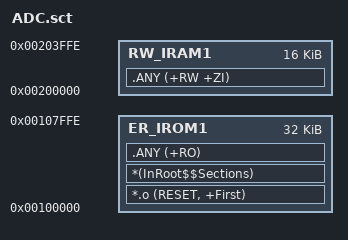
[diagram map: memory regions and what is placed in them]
; *************************************************************
; *** Scatter-Loading Description File generated by uVision ***
; *************************************************************

LR_IROM1 0x00100000 0x00007FFF  {    ; load region size_region
  ER_IROM1 0x00100000 0x00007FFF  {  ; load address = execution address
   *.o (RESET, +First)
   *(InRoot$$Sections)
   .ANY (+RO)
  }
  RW_IRAM1 0x00200000 0x00003FFF  {  ; RW data
   .ANY (+RW +ZI)
  }
}

